# TOP_RCM_TOP_RCM_53200000h register map
Vendor: Texas Instruments
Peripheral module from a debugger description file (folder AM261x).
Registers are 32-bit, read-write, reset 0x0 unless marked. A register's access mark holds for its fields unless they carry their own. Offsets are as the file gives them; lines under a group give offsets from that group; [hi:lo] are bit positions; {n}, {i} and the like mark numbered series; 'fields as' and 'values as' point back to an identical list; <NAME> marks a mode.

## TOP_RCM (part 1 of 2)
0x808 TOP_RCM_PLL_PER_TENABLE — PLL_PER_TENABLE refer to PLL spec for complete functional description of the below bitfields.
  [0] PLL_PER_TENABLE_TENABLE — Signal TENABLE loads REGM, REGN, REGSD and SELFREQDCO data. M, N. SD and SELFREQDCO latch [active rise edge]
0x80C TOP_RCM_PLL_PER_TENABLEDIV — PLL_PER_TENABLEDIV refer to PLL spec for complete functional description of the below bitfields.
  [0] PLL_PER_TENABLEDIV_TENABLEDIV — TENABLEDIV rising edge loads the values of M2REG and N2REG into ADPLLLJ register. TENABLEDIV could be activated anytime when the DPLL digital is in power-up condition. M2 and N2 latch [active rise edge]
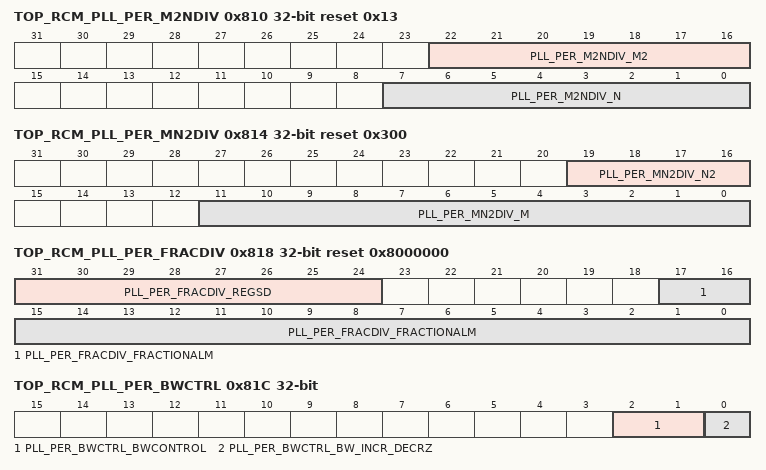
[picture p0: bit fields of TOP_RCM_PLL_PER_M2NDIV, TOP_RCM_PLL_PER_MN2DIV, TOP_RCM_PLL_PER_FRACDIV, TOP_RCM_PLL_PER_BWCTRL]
0x810 TOP_RCM_PLL_PER_M2NDIV reset 0x13 — PLL_PER_M2NDIV refer to PLL spec for complete functional description of the below bitfields.
  [22:16] PLL_PER_M2NDIV_M2 — Post-divider is REGM2
  [7:0] PLL_PER_M2NDIV_N — Pre-divider is REGN+1
0x814 TOP_RCM_PLL_PER_MN2DIV reset 0x300 — PLL_PER_MN2DIV refer to PLL spec for complete functional description of the below bitfields.
  [19:16] PLL_PER_MN2DIV_N2 — Bypass divider is REGN2+1
  [11:0] PLL_PER_MN2DIV_M — Feedback Multiplier is REGM
0x818 TOP_RCM_PLL_PER_FRACDIV reset 0x8000000 — PLL_PER_FRACDIV refer to PLL spec for complete functional description of the below bitfields.
  [31:24] PLL_PER_FRACDIV_REGSD — Sigma-Delta DividerShould be set by s/w to provide optimum jitter performance.DPLL_SD_DIV = CEILING [[DPLL_MULT/[DPLL_DIV+1]] * CLKINP/ 250], where CLKINP is the input clock of the DPLL in MHz
  [17:0] PLL_PER_FRACDIV_FRACTIONALM — Fractional part of the M divider.The 18bit FractionalM value is loaded into DPLL on the rising edge of TENABLE signal .To enable Integer only division FractionalM should be set to 18'b0.
0x81C TOP_RCM_PLL_PER_BWCTRL — PLL_PER_BWCTRL refer to PLL spec for complete functional description of the below bitfields.
  [2:1] PLL_PER_BWCTRL_BWCONTROL — Change Loop Bandwidth
  [0] PLL_PER_BWCTRL_BW_INCR_DECRZ — Direction of Loop Bandwidth0x0 : decrease BW0x1 : increase BW
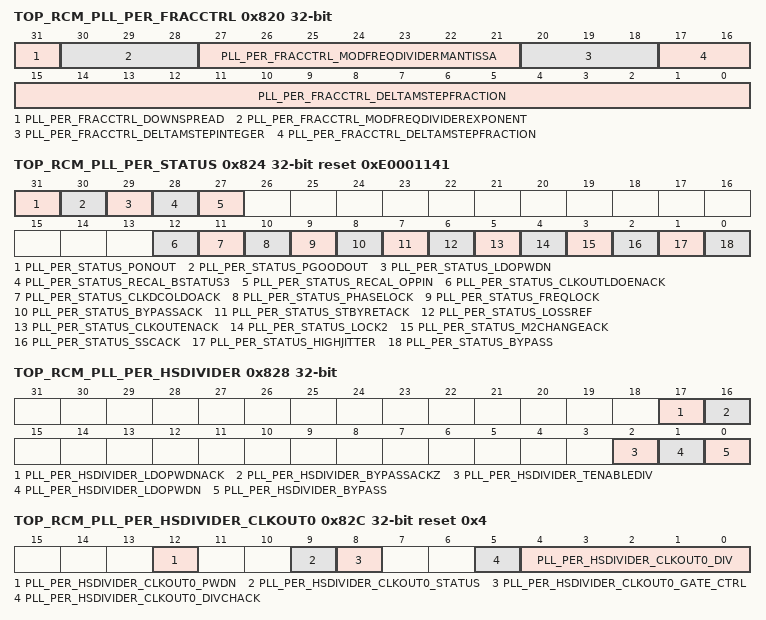
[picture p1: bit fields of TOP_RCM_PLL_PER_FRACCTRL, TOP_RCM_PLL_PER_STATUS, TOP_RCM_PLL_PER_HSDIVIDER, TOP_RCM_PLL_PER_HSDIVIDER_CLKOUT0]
0x820 TOP_RCM_PLL_PER_FRACCTRL — PLL_PER_FRACCTRL refer to PLL spec for complete functional description of the below bitfields.
  [31] PLL_PER_FRACCTRL_DOWNSPREAD — Controls frequency spread0x0 : enables both side frequency spread about the programmed frequency.0x1 : enables low frequency spread only
  [30:28] PLL_PER_FRACCTRL_MODFREQDIVIDEREXPONENT — Exponent of the REFCLK divider to define the modulation frequency.
  [27:21] PLL_PER_FRACCTRL_MODFREQDIVIDERMANTISSA — Mantissa of the REFCLK divider to define the modulation frequency
  [20:18] PLL_PER_FRACCTRL_DELTAMSTEPINTEGER — Integer part of Frequency Spread control
  [17:0] PLL_PER_FRACCTRL_DELTAMSTEPFRACTION — The fraction part of Frequency Spread control
0x824 TOP_RCM_PLL_PER_STATUS ro reset 0xE0001141 — PLL_PER_STATUS refer to PLL spec for complete functional description of the below bitfields.
  [31] PLL_PER_STATUS_PONOUT — Status of the weak power-switch0x0 : indicates the/OFF status of the weak power-switch in digital toSOC.0x1 : ndicates the ON status of the weak power-switch in digital toSOC.
  [30] PLL_PER_STATUS_PGOODOUT — Status of the strong power-switch0x0 : indicates the/OFF status of the strong power-switch in digital toSOC.0x1 : ndicates the ON status of the strong power-switch in digital toSOC.
  [29] PLL_PER_STATUS_LDOPWDN — 1'b1 indicates ADPLLLJ internal LDO is power down. VDDLDOOUT willbe un-defined in this condition
  [28] PLL_PER_STATUS_RECAL_BSTATUS3 — Recalibration status flag. 1 ADPLLLJ requires recalibration
  [27] PLL_PER_STATUS_RECAL_OPPIN — Recalibration status flag. 1 ADPLLLJ requires recalibration
  [12] PLL_PER_STATUS_CLKOUTLDOENACK — Indicates the enable/disable condition of CLKOUTLDOEN0x0 = CLKOUTLDO gating completed0x1 = CLKOUTLDO enabling completed
  [11] PLL_PER_STATUS_CLKDCOLDOACK — Indicates the enable/disable condition of CLKDCOLDOEN0x0 = CLKDCOLDO gating completed0x1 = CLKDCOLDO enabling completed
  [10] PLL_PER_STATUS_PHASELOCK — Status on PHASELOCK output pin
  [9] PLL_PER_STATUS_FREQLOCK — Status on FREQLOCK output pin
  [8] PLL_PER_STATUS_BYPASSACK — Status of BYPASSACK output pin
  [7] PLL_PER_STATUS_STBYRETACK — Standby and retention status0x0: indicates to SOC that all internal clocks in ADPLLLJ are activeand it is starting the relock process.0x1: indicates to SOC that all internal clocks in ADPLLLJ are gatedand it is ready for retention.
  [6] PLL_PER_STATUS_LOSSREF — Reference input loss is indicated by 1'b0.
  [5] PLL_PER_STATUS_CLKOUTENACK — Indicates the enable/disable condition of CLKOUTEN0x0 = CLKOUT gating completed0x1 = CLKOUT enabling completed
  [4] PLL_PER_STATUS_LOCK2 — ADPLL internal loop lock status
  [3] PLL_PER_STATUS_M2CHANGEACK — Acknowledge for change to M2 divider. Toggles from 1-0 or 0-1[depending on current value] once CLKOUT frequency change hascompleted.
  [2] PLL_PER_STATUS_SSCACK — Spread Spectrum status0x0 : Spread-spectrum Clocking is disabled on output clocks0x1 : Spread-spectrum Clocking is enabled on output clocks
  [1] PLL_PER_STATUS_HIGHJITTER — 1'b1 indicates jitter. After PHASELOCK is asserted high, theHIGHJITTER flag is asserted high if phase error between REFCLKand FBCLK greater than 24%.
  [0] PLL_PER_STATUS_BYPASS — Bypass status signal. 1 CLKOUT in bypass
0x828 TOP_RCM_PLL_PER_HSDIVIDER access per field — PLL_PER_HSDIVIDER refer to HSDIVIDER spec for complete functional description of the below bitfields.
  [17] PLL_PER_HSDIVIDER_LDOPWDNACK ro — LDO Power Down Ack
  [16] PLL_PER_HSDIVIDER_BYPASSACKZ ro — HSDIVIDER Bypass Ack
  [2] PLL_PER_HSDIVIDER_TENABLEDIV rw — TENABLEDIV rising edge loads the values of M2REG and N2REG into ADPLLLJ register. TENABLEDIV could be activated anytime when the DPLL digital is in power-up condition. M2 and N2 latch [active rise edge]
  [1] PLL_PER_HSDIVIDER_LDOPWDN rw — 1'b1 indicates ADPLLLJ internal LDO is power down. VDDLDOOUT willbe un-defined in this condition
  [0] PLL_PER_HSDIVIDER_BYPASS rw — HSDIVIDER Bypass
0x82C TOP_RCM_PLL_PER_HSDIVIDER_CLKOUT0 access per field reset 0x4 — PLL_PER_HSDIVIDER_CLKOUT0 refer to HSDIVIDER spec for complete functional description of the below bitfields.
  [12] PLL_PER_HSDIVIDER_CLKOUT0_PWDN rw — Power down for HSDIVIDER CLKOUT0 divider and hence CLKOUT0 output0h[R/W] = CLKOUT0 divider active1h[R/W] = CLKOUT0 divider is powered down
  [9] PLL_PER_HSDIVIDER_CLKOUT0_STATUS ro — HSDIVIDER CLKOUT0 status0h[R] = The clock output is gated1h[R] = The clock output is enabled
  [8] PLL_PER_HSDIVIDER_CLKOUT0_GATE_CTRL rw — Control gating of HSDIVIDER CLKOUT00h[R/W] = Automatically gate this clock when there is nodependency for it1h[R/W] = Force this clock to stay enabled even if there is norequest
  [5] PLL_PER_HSDIVIDER_CLKOUT0_DIVCHACK ro — Toggle on this status bit after changing HSDIVIDER_CLKOUT0_DIVindicates that the change in divider value has taken effect
  [4:0] PLL_PER_HSDIVIDER_CLKOUT0_DIV rw — DPLL post-divider factor, HSDIVIDER CLKOUT0, for internal clock generation.Divide values from 1 to 31.0h[R/W] = Reserved
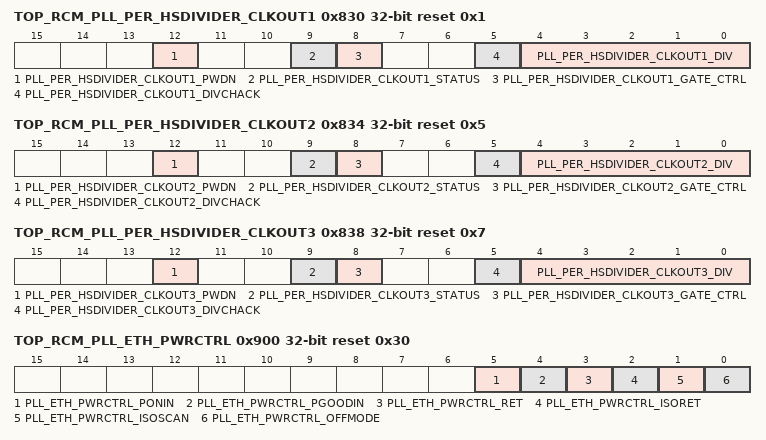
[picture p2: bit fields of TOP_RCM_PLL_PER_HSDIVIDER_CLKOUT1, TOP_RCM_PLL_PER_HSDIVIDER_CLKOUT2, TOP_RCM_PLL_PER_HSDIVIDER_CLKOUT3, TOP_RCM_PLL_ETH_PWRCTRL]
0x830 TOP_RCM_PLL_PER_HSDIVIDER_CLKOUT1 access per field reset 0x1 — PLL_PER_HSDIVIDER_CLKOUT1 refer to HSDIVIDER spec for complete functional description of the below bitfields.
  [12] PLL_PER_HSDIVIDER_CLKOUT1_PWDN rw — Power down for HSDIVIDER CLKOUT1 divider and hence CLKOUT1 output0h[R/W] = CLKOUT1 divider active1h[R/W] = CLKOUT1 divider is powered down
  [9] PLL_PER_HSDIVIDER_CLKOUT1_STATUS ro — HSDIVIDER CLKOUT1 status0h[R] = The clock output is gated1h[R] = The clock output is enabled
  [8] PLL_PER_HSDIVIDER_CLKOUT1_GATE_CTRL rw — Control gating of HSDIVIDER CLKOUT10h[R/W] = Automatically gate this clock when there is nodependency for it1h[R/W] = Force this clock to stay enabled even if there is norequest
  [5] PLL_PER_HSDIVIDER_CLKOUT1_DIVCHACK ro — Toggle on this status bit after changing HSDIVIDER_CLKOUT1_DIVindicates that the change in divider value has taken effect
  [4:0] PLL_PER_HSDIVIDER_CLKOUT1_DIV rw — DPLL post-divider factor, HSDIVIDER CLKOUT1, for internal clock generation.Divide values from 1 to 31.0h[R/W] = Reserved
0x834 TOP_RCM_PLL_PER_HSDIVIDER_CLKOUT2 access per field reset 0x5 — PLL_PER_HSDIVIDER_CLKOUT2 refer to HSDIVIDER spec for complete functional description of the below bitfields.
  [12] PLL_PER_HSDIVIDER_CLKOUT2_PWDN rw — Power down for HSDIVIDER CLKOUT2 divider and hence CLKOUT2 output0h[R/W] = CLKOUT2 divider active1h[R/W] = CLKOUT2 divider is powered down
  [9] PLL_PER_HSDIVIDER_CLKOUT2_STATUS ro — HSDIVIDER CLKOUT2 status0h[R] = The clock output is gated1h[R] = The clock output is enabled
  [8] PLL_PER_HSDIVIDER_CLKOUT2_GATE_CTRL rw — Control gating of HSDIVIDER CLKOUT20h[R/W] = Automatically gate this clock when there is nodependency for it1h[R/W] = Force this clock to stay enabled even if there is norequest
  [5] PLL_PER_HSDIVIDER_CLKOUT2_DIVCHACK ro — Toggle on this status bit after changing HSDIVIDER_CLKOUT2_DIVindicates that the change in divider value has taken effect
  [4:0] PLL_PER_HSDIVIDER_CLKOUT2_DIV rw — DPLL post-divider factor, M6, for internal clock generation.Divide values from 1 to 31.0h[R/W] = Reserved
0x838 TOP_RCM_PLL_PER_HSDIVIDER_CLKOUT3 access per field reset 0x7 — PLL_PER_HSDIVIDER_CLKOUT3 refer to HSDIVIDER spec for complete functional description of the below bitfields.
  [12] PLL_PER_HSDIVIDER_CLKOUT3_PWDN rw — Power down for HSDIVIDER CLKOUT3 divider and hence CLKOUT3 output0h[R/W] = CLKOUT3 divider active1h[R/W] = CLKOUT3 divider is powered down
  [9] PLL_PER_HSDIVIDER_CLKOUT3_STATUS ro — HSDIVIDER CLKOUT3 status0h[R] = The clock output is gated1h[R] = The clock output is enabled
  [8] PLL_PER_HSDIVIDER_CLKOUT3_GATE_CTRL rw — Control gating of HSDIVIDER CLKOUT30h[R/W] = Automatically gate this clock when there is nodependency for it1h[R/W] = Force this clock to stay enabled even if there is norequest
  [5] PLL_PER_HSDIVIDER_CLKOUT3_DIVCHACK ro — Toggle on this status bit after changing HSDIVIDER_CLKOUT3_DIVindicates that the change in divider value has taken effect
  [4:0] PLL_PER_HSDIVIDER_CLKOUT3_DIV rw — DPLL post-divider factor, HSDIVIDER CLKOUT3, for internal clock generation.Divide values from 1 to 31.0h[R/W] = Reserved
0x83C TOP_RCM_PLL_PER_RSTCTRL — PLL_PER_RSTCTRL.
  [2:0] PLL_PER_RSTCTRL_ASSERT — SW Reset override for the PLLWrite 3'b111 : Override is enabled and Reset is asserted
0x840 TOP_RCM_PLL_PER_HSDIVIDER_RSTCTRL — PLL_PER_HSDIVIDER_RSTCTRL .
  [2:0] PLL_PER_HSDIVIDER_RSTCTRL_ASSERT — SW Reset override for the HSDIVIDERWrite 3'b111 : Override is enabled and Reset is asserted
0x900 TOP_RCM_PLL_ETH_PWRCTRL reset 0x30 — PLL_ETH_PWRCTRL refer to PLL spec for complete functional description of the below bitfields.
  [5] PLL_ETH_PWRCTRL_PONIN — ON/OFF control of the weak power switch digital. For functionalmode it should be 1
  [4] PLL_ETH_PWRCTRL_PGOODIN — ON/OFF control of the strong power switch digital. For functional mode it should be 1
  [3] PLL_ETH_PWRCTRL_RET — Save/Restore control for Retention mode. For functional mode itshould be 0
  [2] PLL_ETH_PWRCTRL_ISORET — Save/Restore control for Isolation of output pins For functional modeit should be 0
  [1] PLL_ETH_PWRCTRL_ISOSCAN — Save/Restore control for Isolation of the Scanout pins. For functionalmode it should be 0
  [0] PLL_ETH_PWRCTRL_OFFMODE — Used to switch OFF the logic on VDDA. For functional mode itshould be 0
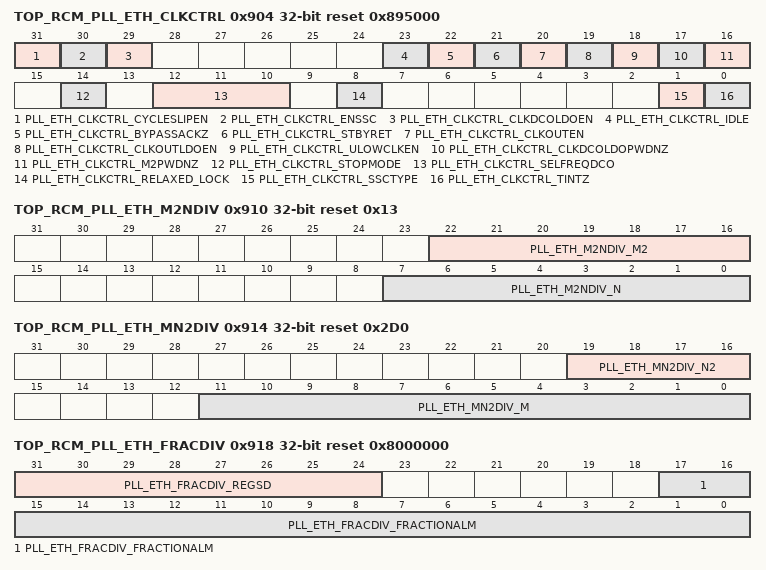
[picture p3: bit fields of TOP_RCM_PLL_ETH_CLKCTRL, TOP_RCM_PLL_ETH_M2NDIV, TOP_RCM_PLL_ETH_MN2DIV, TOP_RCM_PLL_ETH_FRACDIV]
0x904 TOP_RCM_PLL_ETH_CLKCTRL reset 0x895000 — PLL_ETH_CLKCTRL refer to PLL spec for complete functional description of the below bitfields.
  [31] PLL_ETH_CLKCTRL_CYCLESLIPEN — FailSafe enable to trigger re-calibration in case CycleSlip occurs between REFCLK and FBCLK. Cycleslip could be caused if loop is not able to track input clock. Default = 1'b0 recommended
  [30] PLL_ETH_CLKCTRL_ENSSC — Controls Clock SpReading. SSC is not supported. Should be set to 0x0 to disable clock spReading.
  [29] PLL_ETH_CLKCTRL_CLKDCOLDOEN — Synchronously enables/disables CLKDCOLDO0x0 : synchronously disables CLKDCOLDO0x1 : synchronously enables CLKDCOLDO
  [23] PLL_ETH_CLKCTRL_IDLE — Sets PLL to Idle mode0x0 : When SYSRESET = 0 and TINITZ = 1 IDLE = 0 PLL will go toActive and Locked0x1 : When SYSRESET = 0 and TINITZ = 1 IDLE = 1 PLL will go toIdle Bypass low powe
  [22] PLL_ETH_CLKCTRL_BYPASSACKZ — BYPASSACKZ is a special purpose input to the module. In generalthis input is expected to be tied to static low. For the output clocks ofthe module that do not have an internal bypass mux viz.CLKDCOLDO and CLKOUTLDO, a bypass mux could beimplemented external to the module.
  [21] PLL_ETH_CLKCTRL_STBYRET — Standby retention control0x0 : prepares ADPLLLJ for relock when out of retention byremoving the gating on all internal clocks.0x1 : prepares ADPLLLJ for retention by gating all the internalclocks.
  [20] PLL_ETH_CLKCTRL_CLKOUTEN — CLKOUT enable or disable0x0 : synchronously disables CLKOUT0x1 : synchronously enables CLKOUT
  [19] PLL_ETH_CLKCTRL_CLKOUTLDOEN — Synchronously enables/disables CLKOUTLDO 0x0 : synchronously disables CLKOUTLDO 0x1 : synchronously enables CLKOUTLDO
  [18] PLL_ETH_CLKCTRL_ULOWCLKEN — Select CLKOUT source in bypass0x0: When ADPLLLJ in bypass mode, CLKOUT = CLKINP/[N2+1]0x1: When ADPLLLJ in bypass mode, CLKOUT = CLKINPULOW.
  [17] PLL_ETH_CLKCTRL_CLKDCOLDOPWDNZ — 0 Asynchronous power down for CLKDCOLDO o/p.
  [16] PLL_ETH_CLKCTRL_M2PWDNZ — M2 divider power down mode0x0: Asynchronous power down for M2 divider0x1 : M2 divider is functional
  [14] PLL_ETH_CLKCTRL_STOPMODE — When in Lossclk/Stbyret 0x0 : Limp mode 0x1 : Stopmode
  [12:10] PLL_ETH_CLKCTRL_SELFREQDCO — DCO Clock [DCOCLK = CLKINP * [M/[N+1]]] frequency rangeselector.0x0: Reserved0x2: HS2 : DCOCLK range is from 500 MHz to1000MHz0x3: Reserved0x4: HS1: DCOCLK range is from1000MHz to2000MHz0x5: Reserved
  [8] PLL_ETH_CLKCTRL_RELAXED_LOCK — Decides when FREQLOCK asserted0x0: FREQLOCK asserted when DC frequency error less than 1%0x1: FREQLOCK asserted when DC frequency error less than 2%
  [1] PLL_ETH_CLKCTRL_SSCTYPE — SSC Type - This should be configured as 1'b0. The module supports spread spectrum clocking [SSC] on its output clocks.
  [0] PLL_ETH_CLKCTRL_TINTZ — PLL core soft reset. TINITZ activation [Low] gives softreset to ADPLLLJ. TINITZ does not reset the entire digital control logic; it forces the FSM into RESET State so that ADPLLLJ could restart.
0x908 TOP_RCM_PLL_ETH_TENABLE — PLL_ETH_TENABLE refer to PLL spec for complete functional description of the below bitfields.
  [0] PLL_ETH_TENABLE_TENABLE — Signal TENABLE loads REGM, REGN, REGSD and SELFREQDCO data. M, N. SD and SELFREQDCO latch [active rise edge]
0x90C TOP_RCM_PLL_ETH_TENABLEDIV — PLL_ETH_TENABLEDIV refer to PLL spec for complete functional description of the below bitfields.
  [0] PLL_ETH_TENABLEDIV_TENABLEDIV — TENABLEDIV rising edge loads the values of M2REG and N2REG into ADPLLLJ register. TENABLEDIV could be activated anytime when the DPLL digital is in power-up condition. M2 and N2 latch [active rise edge]
0x910 TOP_RCM_PLL_ETH_M2NDIV reset 0x13 — PLL_ETH_M2NDIV refer to PLL spec for complete functional description of the below bitfields.
  [22:16] PLL_ETH_M2NDIV_M2 — Post-divider is REGM2
  [7:0] PLL_ETH_M2NDIV_N — Pre-divider is REGN+1
0x914 TOP_RCM_PLL_ETH_MN2DIV reset 0x2D0 — PLL_ETH_MN2DIV refer to PLL spec for complete functional description of the below bitfields.
  [19:16] PLL_ETH_MN2DIV_N2 — Bypass divider is REGN2+1
  [11:0] PLL_ETH_MN2DIV_M — Feedback Multiplier is REGM
0x918 TOP_RCM_PLL_ETH_FRACDIV reset 0x8000000 — PLL_ETH_FRACDIV refer to PLL spec for complete functional description of the below bitfields.
  [31:24] PLL_ETH_FRACDIV_REGSD — Sigma-Delta DividerShould be set by s/w to provide optimum jitter performance.DPLL_SD_DIV = CEILING [[DPLL_MULT/[DPLL_DIV+1]] * CLKINP/ 250], where CLKINP is the input clock of the DPLL in MHz
  [17:0] PLL_ETH_FRACDIV_FRACTIONALM — Fractional part of the M divider.The 18bit FractionalM value is loaded into DPLL on the rising edge of TENABLE signal .To enable Integer only division FractionalM should be set to 18'b0.
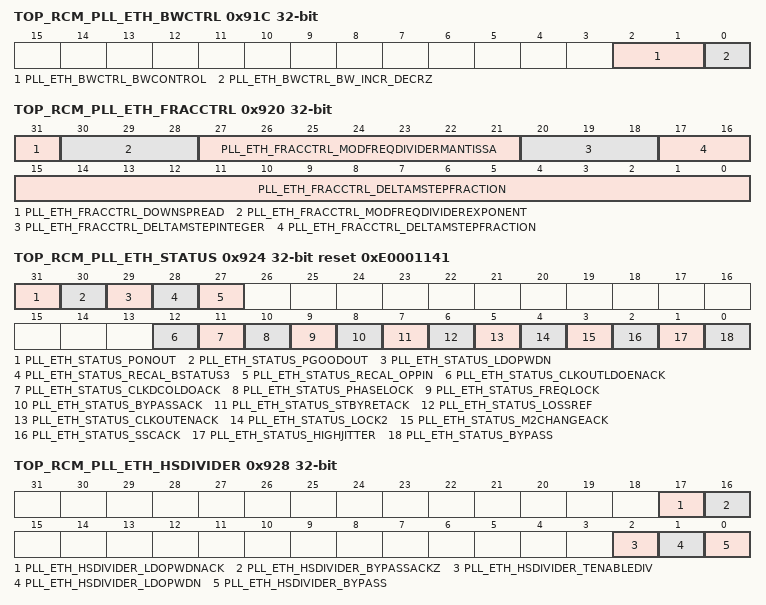
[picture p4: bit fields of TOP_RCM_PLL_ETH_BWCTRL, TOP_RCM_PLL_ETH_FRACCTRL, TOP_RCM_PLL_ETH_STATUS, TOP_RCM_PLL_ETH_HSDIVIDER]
0x91C TOP_RCM_PLL_ETH_BWCTRL — PLL_ETH_BWCTRL refer to PLL spec for complete functional description of the below bitfields.
  [2:1] PLL_ETH_BWCTRL_BWCONTROL — Change Loop Bandwidth
  [0] PLL_ETH_BWCTRL_BW_INCR_DECRZ — Direction of Loop Bandwidth0x0 : decrease BW0x1 : increase BW
0x920 TOP_RCM_PLL_ETH_FRACCTRL — PLL_ETH_FRACCTRL refer to PLL spec for complete functional description of the below bitfields.
  [31] PLL_ETH_FRACCTRL_DOWNSPREAD — Controls frequency spread0x0 : enables both side frequency spread about the programmed frequency.0x1 : enables low frequency spread only
  [30:28] PLL_ETH_FRACCTRL_MODFREQDIVIDEREXPONENT — Exponent of the REFCLK divider to define the modulation frequency.
  [27:21] PLL_ETH_FRACCTRL_MODFREQDIVIDERMANTISSA — Mantissa of the REFCLK divider to define the modulation frequency
  [20:18] PLL_ETH_FRACCTRL_DELTAMSTEPINTEGER — Integer part of Frequency Spread control
  [17:0] PLL_ETH_FRACCTRL_DELTAMSTEPFRACTION — The fraction part of Frequency Spread control
0x924 TOP_RCM_PLL_ETH_STATUS ro reset 0xE0001141 — PLL_ETH_STATUS refer to PLL spec for complete functional description of the below bitfields.
  [31] PLL_ETH_STATUS_PONOUT — Status of the weak power-switch0x0 : indicates the/OFF status of the weak power-switch in digital toSOC.0x1 : ndicates the ON status of the weak power-switch in digital toSOC.
  [30] PLL_ETH_STATUS_PGOODOUT — Status of the strong power-switch0x0 : indicates the/OFF status of the strong power-switch in digital toSOC.0x1 : ndicates the ON status of the strong power-switch in digital toSOC.
  [29] PLL_ETH_STATUS_LDOPWDN — 1'b1 indicates ADPLLLJ internal LDO is power down. VDDLDOOUT willbe un-defined in this condition
  [28] PLL_ETH_STATUS_RECAL_BSTATUS3 — Recalibration status flag. 1 ADPLLLJ requires recalibration
  [27] PLL_ETH_STATUS_RECAL_OPPIN — Recalibration status flag. 1 ADPLLLJ requires recalibration
  [12] PLL_ETH_STATUS_CLKOUTLDOENACK — Indicates the enable/disable condition of CLKOUTLDOEN0x0 = CLKOUTLDO gating completed0x1 = CLKOUTLDO enabling completed
  [11] PLL_ETH_STATUS_CLKDCOLDOACK — Indicates the enable/disable condition of CLKDCOLDOEN0x0 = CLKDCOLDO gating completed0x1 = CLKDCOLDO enabling completed
  [10] PLL_ETH_STATUS_PHASELOCK — Status on PHASELOCK output pin
  [9] PLL_ETH_STATUS_FREQLOCK — Status on FREQLOCK output pin
  [8] PLL_ETH_STATUS_BYPASSACK — Status of BYPASSACK output pin
  [7] PLL_ETH_STATUS_STBYRETACK — Standby and retention status0x0: indicates to SOC that all internal clocks in ADPLLLJ are activeand it is starting the relock process.0x1: indicates to SOC that all internal clocks in ADPLLLJ are gatedand it is ready for retention.
  [6] PLL_ETH_STATUS_LOSSREF — Reference input loss is indicated by 1'b0.
  [5] PLL_ETH_STATUS_CLKOUTENACK — Indicates the enable/disable condition of CLKOUTEN0x0 = CLKOUT gating completed0x1 = CLKOUT enabling completed
  [4] PLL_ETH_STATUS_LOCK2 — ADPLL internal loop lock status
  [3] PLL_ETH_STATUS_M2CHANGEACK — Acknowledge for change to M2 divider. Toggles from 1-0 or 0-1[depending on current value] once CLKOUT frequency change hascompleted.
  [2] PLL_ETH_STATUS_SSCACK — Spread Spectrum status0x0 : Spread-spectrum Clocking is disabled on output clocks0x1 : Spread-spectrum Clocking is enabled on output clocks
  [1] PLL_ETH_STATUS_HIGHJITTER — 1'b1 indicates jitter. After PHASELOCK is asserted high, theHIGHJITTER flag is asserted high if phase error between REFCLKand FBCLK greater than 24%.
  [0] PLL_ETH_STATUS_BYPASS — Bypass status signal. 1 CLKOUT in bypass
0x928 TOP_RCM_PLL_ETH_HSDIVIDER access per field — PLL_ETH_HSDIVIDER refer to HSDIVIDER spec for complete functional description of the below bitfields.
  [17] PLL_ETH_HSDIVIDER_LDOPWDNACK ro — LDO Power Down Ack
  [16] PLL_ETH_HSDIVIDER_BYPASSACKZ ro — HSDIVIDER Bypass Ack
  [2] PLL_ETH_HSDIVIDER_TENABLEDIV rw — TENABLEDIV rising edge loads the values of M2REG and N2REG into ADPLLLJ register. TENABLEDIV could be activated anytime when the DPLL digital is in power-up condition. M2 and N2 latch [active rise edge]
  [1] PLL_ETH_HSDIVIDER_LDOPWDN rw — 1'b1 indicates ADPLLLJ internal LDO is power down. VDDLDOOUT willbe un-defined in this condition
  [0] PLL_ETH_HSDIVIDER_BYPASS rw — HSDIVIDER Bypass
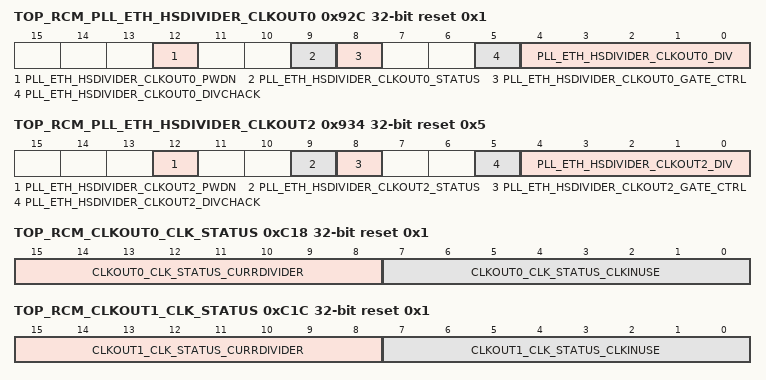
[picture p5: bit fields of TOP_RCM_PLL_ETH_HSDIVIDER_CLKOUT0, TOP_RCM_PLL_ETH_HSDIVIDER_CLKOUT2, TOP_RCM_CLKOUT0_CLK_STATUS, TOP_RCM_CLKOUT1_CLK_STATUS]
0x92C TOP_RCM_PLL_ETH_HSDIVIDER_CLKOUT0 access per field reset 0x1 — PLL_ETH_HSDIVIDER_CLKOUT0 refer to HSDIVIDER spec for complete functional description of the below bitfields.
  [12] PLL_ETH_HSDIVIDER_CLKOUT0_PWDN rw — Power down for HSDIVIDER CLKOUT0 divider and hence CLKOUT0 output0h[R/W] = CLKOUT0 divider active1h[R/W] = CLKOUT0 divider is powered down
  [9] PLL_ETH_HSDIVIDER_CLKOUT0_STATUS ro — HSDIVIDER CLKOUT0 status0h[R] = The clock output is gated1h[R] = The clock output is enabled
  [8] PLL_ETH_HSDIVIDER_CLKOUT0_GATE_CTRL rw — Control gating of HSDIVIDER CLKOUT00h[R/W] = Automatically gate this clock when there is nodependency for it1h[R/W] = Force this clock to stay enabled even if there is norequest
  [5] PLL_ETH_HSDIVIDER_CLKOUT0_DIVCHACK ro — Toggle on this status bit after changing HSDIVIDER_CLKOUT0_DIVindicates that the change in divider value has taken effect
  [4:0] PLL_ETH_HSDIVIDER_CLKOUT0_DIV rw — DPLL post-divider factor, HSDIVIDER CLKOUT0, for internal clock generation.Divide values from 1 to 31.0h[R/W] = Reserved
0x934 TOP_RCM_PLL_ETH_HSDIVIDER_CLKOUT2 access per field reset 0x5 — PLL_ETH_HSDIVIDER_CLKOUT2 refer to HSDIVIDER spec for complete functional description of the below bitfields.
  [12] PLL_ETH_HSDIVIDER_CLKOUT2_PWDN rw — Power down for HSDIVIDER CLKOUT2 divider and hence CLKOUT2 output0h[R/W] = CLKOUT2 divider active1h[R/W] = CLKOUT2 divider is powered down
  [9] PLL_ETH_HSDIVIDER_CLKOUT2_STATUS ro — HSDIVIDER CLKOUT2 status0h[R] = The clock output is gated1h[R] = The clock output is enabled
  [8] PLL_ETH_HSDIVIDER_CLKOUT2_GATE_CTRL rw — Control gating of HSDIVIDER CLKOUT20h[R/W] = Automatically gate this clock when there is nodependency for it1h[R/W] = Force this clock to stay enabled even if there is norequest
  [5] PLL_ETH_HSDIVIDER_CLKOUT2_DIVCHACK ro — Toggle on this status bit after changing HSDIVIDER_CLKOUT2_DIVindicates that the change in divider value has taken effect
  [4:0] PLL_ETH_HSDIVIDER_CLKOUT2_DIV rw — DPLL post-divider factor, M6, for internal clock generation.Divide values from 1 to 31.0h[R/W] = Reserved
0x93C TOP_RCM_PLL_ETH_RSTCTRL — PLL_ETH_RSTCTRL.
  [2:0] PLL_ETH_RSTCTRL_ASSERT — SW Reset override for the PLLWrite 3'b111 : Override is enabled and Reset is asserted
0x940 TOP_RCM_PLL_ETH_HSDIVIDER_RSTCTRL — PLL_ETH_HSDIVIDER_RSTCTRL .
  [2:0] PLL_ETH_HSDIVIDER_RSTCTRL_ASSERT — SW Reset override for the HSDIVIDERWrite 3'b111 : Override is enabled and Reset is asserted
0xC00 TOP_RCM_CLKOUT0_CLK_SRC_SEL — Clock Source select register for CLKOUT clock.
  [11:0] CLKOUT0_CLK_SRC_SEL_CLKSRCSEL — Select line for selecting source clock for MSS CLKOUT .Data should be loaded as multibit. For example: if Clock source 0x5 should be selected then 0x555 should be configured to the register.Use the following values to select clk src-0x000 - WUCPUCLK0x111 - DPLL_CORE_HSDIV0_CLKOUT00x222 - DPLL_CORE_HSDIV0_CLKOUT10x333 - DPLL_ETH_HSDIV0_CLKOUT00x444 - DPLL_PER_HSDIV0_CLKOUT10x555 - RCCLK10M_NOGATE0x666 - RCCLK32K0x777 - CTPS_GENF0
0xC04 TOP_RCM_CLKOUT1_CLK_SRC_SEL — Clock Source select register for CLKOUT clock.
  [11:0] CLKOUT1_CLK_SRC_SEL_CLKSRCSEL — Select line for selecting source clock for MSS CLKOUT .Data should be loaded as multibit. For example: if Clock source 0x5 should be selected then 0x555 should be configured to the register.Use the following values to select clk src-0x000 - WUCPUCLK0x111 - DPLL_CORE_HSDIV0_CLKOUT00x222 - DPLL_CORE_HSDIV0_CLKOUT10x333 - DPLL_ETH_HSDIV0_CLKOUT00x444 - DPLL_PER_HSDIV0_CLKOUT10x555 - RCCLK10M_NOGATE0x666 - RCCLK32K0x777 - CTPS_GENF0
0xC08 TOP_RCM_CLKOUT0_DIV_VAL — Clock Divider register for CLKOUT clock.
  [11:0] CLKOUT0_DIV_VAL_CLKDIV — Divider value for CLKOUT selected clock..To set the divider value of [n+1] configure the register to '0xnnn'.Data should be loaded as multibit. For example: if divider value of '0x9' is required then '0x888' should be configured to the register.
0xC0C TOP_RCM_CLKOUT1_DIV_VAL — Clock Divider register for CLKOUT clock.
  [11:0] CLKOUT1_DIV_VAL_CLKDIV — Divider value for CLKOUT selected clock..To set the divider value of [n+1] configure the register to '0xnnn'.Data should be loaded as multibit. For example: if divider value of '0x9' is required then '0x888' should be configured to the register.
0xC10 TOP_RCM_CLKOUT0_CLK_GATE — Clock Gating register for CLKOUT clock.
  [2:0] CLKOUT0_CLK_GATE_GATED — Only for debug- Functionality not guaranteed Clock gating config for MSS CLKOUTData should be loaded as multibit. Write 3'b000 : Clock is ungated [multibit 000]Write 3'b111 : Clock is gated [multibit 111]
0xC14 TOP_RCM_CLKOUT1_CLK_GATE — Clock Gating register for CLKOUT clock.
  [2:0] CLKOUT1_CLK_GATE_GATED — Only for debug- Functionality not guaranteed Clock gating config for MSS CLKOUTData should be loaded as multibit. Write 3'b000 : Clock is ungated [multibit 000]Write 3'b111 : Clock is gated [multibit 111]
0xC18 TOP_RCM_CLKOUT0_CLK_STATUS ro reset 0x1 — Clock Status register for CLKOUT clock.
  [15:8] CLKOUT0_CLK_STATUS_CURRDIVIDER — Status shows the current divider value choosen for CLKOUT Clock
  [7:0] CLKOUT0_CLK_STATUS_CLKINUSE — Status shows the source clock slected for CLKOUT Clock
0xC1C TOP_RCM_CLKOUT1_CLK_STATUS ro reset 0x1 — Clock Status register for CLKOUT clock.
  [15:8] CLKOUT1_CLK_STATUS_CURRDIVIDER — Status shows the current divider value choosen for CLKOUT Clock
  [7:0] CLKOUT1_CLK_STATUS_CLKINUSE — Status shows the source clock slected for CLKOUT Clock
0xC20 TOP_RCM_TRCCLKOUT_CLK_SRC_SEL — Clock Source select register for TRC clksout.
  [11:0] TRCCLKOUT_CLK_SRC_SEL_CLKSRCSEL — Select line for selecting source clock for TRC ClkoutData should be loaded as multibit. For example: if Clock source 0x5 should be selected then 0x555 should be configured to the register.Use the following values to select clk src-0x000 - WUCPUCLK0x111 - DPLL_CORE_HSDIV0_CLKOUT00x222 - DPLL_CORE_HSDIV0_CLKOUT10x333 - DPLL_PER_HSDIV0_CLKOUT00x444 - DPLL_PER_HSDIV0_CLKOUT10x555 - RCCLK10M0x666 - XTALCLK0x777 - RCCLK10M
0xC24 TOP_RCM_TRCCLKOUT_DIV_VAL — Clock Divider register for TRC clksout.
  [11:0] TRCCLKOUT_DIV_VAL_CLKDIV — Divider value for TRCCLKOUT selected clock..To set the divider value of [n+1] configure the register to '0xnnn'.Data should be loaded as multibit. For example: if divider value of '0x9' is required then '0x888' should be configured to the register.
0xC28 TOP_RCM_TRCCLKOUT_CLK_GATE — Clock Gating register for TRC clksout.
  [2:0] TRCCLKOUT_CLK_GATE_GATED — Clock gatring config for TRC ClkoutData should be loaded as multibit. Write 3'b000 : Clock is ungated [multibit 000]Write 3'b111 : Clock is gated [multibit 111]
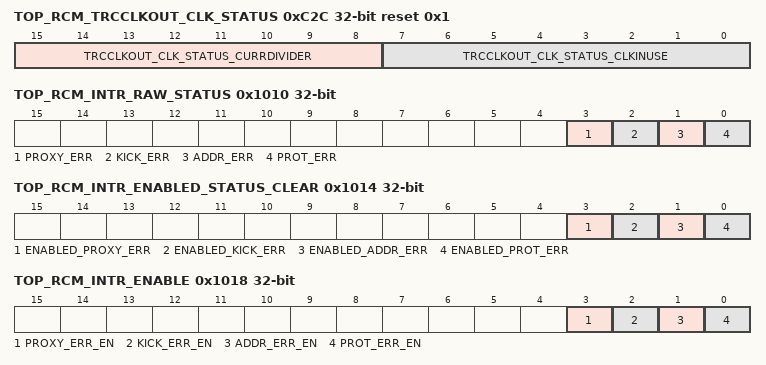
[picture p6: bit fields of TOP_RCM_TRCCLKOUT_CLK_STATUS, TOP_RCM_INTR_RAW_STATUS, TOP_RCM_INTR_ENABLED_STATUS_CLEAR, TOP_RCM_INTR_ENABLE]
0xC2C TOP_RCM_TRCCLKOUT_CLK_STATUS ro reset 0x1 — Clock Status register for TRC clksout.
  [15:8] TRCCLKOUT_CLK_STATUS_CURRDIVIDER — Status shows the current divider value choosen for PMIC Clkout Clock
  [7:0] TRCCLKOUT_CLK_STATUS_CLKINUSE — Status shows the source clock slected for PMIC Clkout Clock
0xC30 TOP_RCM_VMON_CLK_DIV_VAL reset 0x181818 — Clock Divider register for VMON clock.
  [23:0] VMON_CLK_DIV_VAL_CLKDIV — Clock Divider register for VMON clock. To set the divider value of [n+1] configure the register to value of '0xnnn'.Data should be loaded as multibit. For example: if divider value of '0x15' is required then '0x151515' should be configured to the register.
0xC34 TOP_RCM_VMON_CLK_STATUS ro reset 0x1800 — Clock Status register for VMON clock.
  [15:8] VMON_CLK_STATUS_CURRDIVIDER — Clock Status register for VMON clock
0x1008 TOP_RCM_LOCK0_KICK0 — - KICK0 component.
  [31:0] LOCK0_KICK0 — - KICK0 component
0x100C TOP_RCM_LOCK0_KICK1 — - KICK1 component.
  [31:0] LOCK0_KICK1 — - KICK1 component
0x1010 TOP_RCM_INTR_RAW_STATUS access not given — Interrupt Raw Status/Set Register.
  [3] PROXY_ERR — Proxy0 access violation error. Raw status is read. Write a 1 to set the status. Writing a 0 has no effect. (access R/W1TS)
  [2] KICK_ERR — Kick access violation error. Raw status is read. Write a 1 to set the status. Writing a 0 has no effect. (access R/W1TS)
  [1] ADDR_ERR — Addressing violation error. Raw status is read. Write a 1 to set the status. Writing a 0 has no effect. (access R/W1TS)
  [0] PROT_ERR — Protection violation error. Raw status is read. Write a 1 to set the status. Writing a 0 has no effect. (access R/W1TS)
0x1014 TOP_RCM_INTR_ENABLED_STATUS_CLEAR access not given — Interrupt Enabled Status/Clear register.
  [3] ENABLED_PROXY_ERR — Proxy0 access violation error. Enabled status is read. Write a 1 to clear the status. Writing a 0 has no effect. (access R/W1TC)
  [2] ENABLED_KICK_ERR — Kick access violation error. Enabled status is read. Write a 1 to clear the status. Writing a 0 has no effect. (access R/W1TC)
  [1] ENABLED_ADDR_ERR — Addressing violation error. Enabled status is read. Write a 1 to clear the status. Writing a 0 has no effect. (access R/W1TC)
  [0] ENABLED_PROT_ERR — Protection violation error. Enabled status is read. Write a 1 to clear the status. Writing a 0 has no effect. (access R/W1TC)
0x1018 TOP_RCM_INTR_ENABLE access not given — Interrupt Enable register.
  [3] PROXY_ERR_EN — Proxy0 access violation error enable. Write a 1 to set the enable. Writing a 0 has no effect. (access R/W1TS)
  [2] KICK_ERR_EN — Kick access violation error enable. Write a 1 to set the enable. Writing a 0 has no effect. (access R/W1TS)
  [1] ADDR_ERR_EN — Addressing violation error enable. Write a 1 to set the enable. Writing a 0 has no effect. (access R/W1TS)
  [0] PROT_ERR_EN — Protection violation error enable. Write a 1 to set the enable. Writing a 0 has no effect. (access R/W1TS)
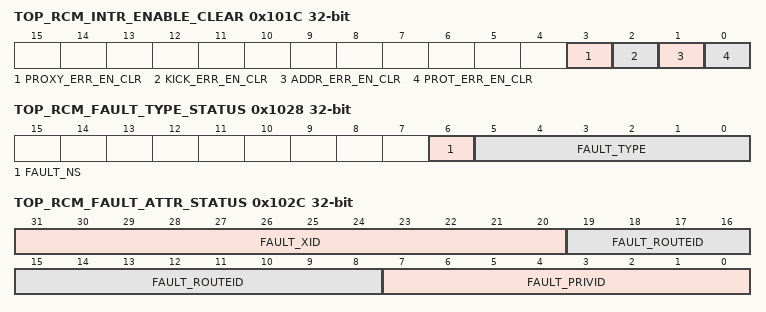
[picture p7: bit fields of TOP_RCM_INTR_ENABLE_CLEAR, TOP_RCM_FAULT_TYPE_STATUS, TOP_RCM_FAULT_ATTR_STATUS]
0x101C TOP_RCM_INTR_ENABLE_CLEAR access not given — Interrupt Enable Clear register.
  [3] PROXY_ERR_EN_CLR — Proxy0 access violation error enable clear. Write a 1 to clear the enable. Writing a 0 has no effect. (access R/W1TC)
  [2] KICK_ERR_EN_CLR — Kick access violation error enable clear. Write a 1 to clear the enable. Writing a 0 has no effect. (access R/W1TC)
  [1] ADDR_ERR_EN_CLR — Addressing violation error enable clear. Write a 1 to clear the enable. Writing a 0 has no effect. (access R/W1TC)
  [0] PROT_ERR_EN_CLR — Protection violation error enable clear. Write a 1 to clear the enable. Writing a 0 has no effect. (access R/W1TC)
0x1020 TOP_RCM_EOI — EOI register.
  [7:0] EOI_VECTOR — EOI vector value. Write this with interrupt distribution value in the chip.
0x1024 TOP_RCM_FAULT_ADDRESS ro — Fault Address register.
  [31:0] FAULT_ADDR — Fault Address.
0x1028 TOP_RCM_FAULT_TYPE_STATUS ro — Fault Type Status register.
  [6] FAULT_NS — Non-secure access.
  [5:0] FAULT_TYPE — Fault Type 10_0000 = Supervisor read fault - priv = 1 dir = 1 dtype != 1 01_0000 = Supervisor write fault - priv = 1 dir = 0 00_1000 = Supervisor execute fault - priv = 1 dir = 1 dtype = 1 00_0100 = User read fault - priv = 0 dir = 1 dtype = 1 00_0010 = User write fault - priv = 0 dir = 0 00_0001 = User execute fault - priv = 0 dir = 1 dtype = 1 00_0000 = No fault
0x102C TOP_RCM_FAULT_ATTR_STATUS ro — Fault Attribute Status register.
  [31:20] FAULT_XID — XID.
  [19:8] FAULT_ROUTEID — Route ID.
  [7:0] FAULT_PRIVID — Privilege ID.
0x1030 TOP_RCM_FAULT_CLEAR wo — Fault Clear register.
  [0] FAULT_CLR — Fault clear. Writing a 1 clears the current fault. Writing a 0 has no effect.
